# f29h85x_hsm_rtdma_ch_regs register map
Vendor: Texas Instruments
Peripheral module from a debugger description file (folder HSM).
Registers are 32-bit, access per field, no defined reset value unless marked. A register's access mark holds for its fields unless they carry their own. Offsets are as the file gives them; lines under a group give offsets from that group; [hi:lo] are bit positions; {n}, {i} and the like mark numbered series; 'fields as' and 'values as' point back to an identical list; <NAME> marks a mode.

## HSM_RTDMA_CH — HSM RTDMA CH Registers
{0x0+0x1000*i} chan_ctrl[{i}] (i=0..7) group
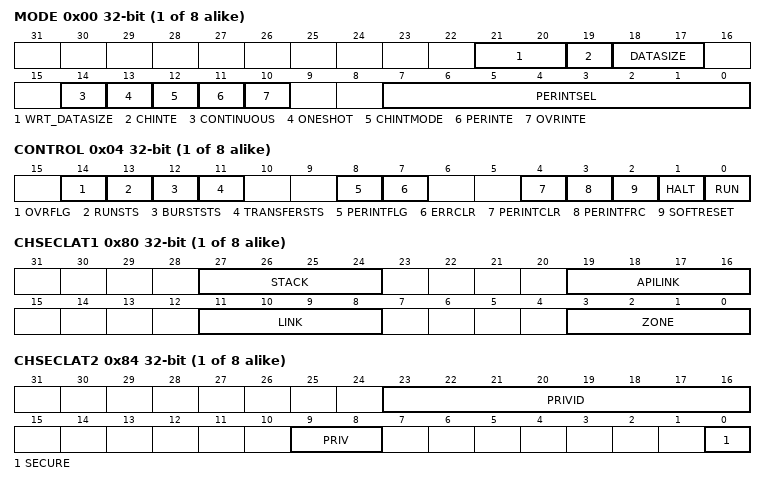
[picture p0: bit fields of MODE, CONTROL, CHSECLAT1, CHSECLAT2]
  0x00 MODE
    [21:20] WRT_DATASIZE rw, [19] CHINTE rw, [18:17] DATASIZE rw, [14] CONTINUOUS rw, [13] ONESHOT rw, [12] CHINTMODE rw, [11] PERINTE rw, [10] OVRINTE rw, [7:0] PERINTSEL rw
  0x04 CONTROL
    [14] OVRFLG ro, [13] RUNSTS ro, [12] BURSTSTS ro, [11] TRANSFERSTS ro, [8] PERINTFLG ro, [7] ERRCLR rw, [4] PERINTCLR rw, [3] PERINTFRC rw, [2] SOFTRESET rw, [1] HALT rw, [0] RUN rw
  0x08 BURST_SIZE
    [7:0] BURSTSIZE rw
  0x0C BURST_COUNT ro
    [7:0] BURSTCOUNT
  0x10 SRC_BURST_STEP
    [15:0] SRCBURSTSTEP rw
  0x14 DST_BURST_STEP
    [15:0] DSTBURSTSTEP rw
  0x18 TRANSFER_SIZE
    [15:0] TRANSFERSIZE rw
  0x1C TRANSFER_COUNT ro
    [15:0] TRANSFERCOUNT
  0x20 SRC_TRANSFER_STEP
    [15:0] SRCTRANSFERSTEP rw
  0x24 DST_TRANSFER_STEP
    [15:0] DSTTRANSFERSTEP rw
  0x28 SRC_WRAP_SIZE
    [15:0] WRAPSIZE rw
  0x2C SRC_WRAP_COUNT ro
    [15:0] WRAPSIZE
  0x30 SRC_WRAP_STEP
    [15:0] WRAPSTEP rw
  0x34 DST_WRAP_SIZE
    [15:0] WRAPSIZE rw
  0x38 DST_WRAP_COUNT ro
    [15:0] WRAPSIZE
  0x3C DST_WRAP_STEP
    [15:0] WRAPSTEP rw
  0x40 SRC_BEG_ADDR_SHADOW rw
    [31:0] BEGADDR
  0x44 SRC_ADDR_SHADOW rw
    [31:0] ADDR
  0x48 SRC_BEG_ADDR_ACTIVE ro
    [31:0] BEGADDR
  0x4C SRC_ADDR_ACTIVE ro
    [31:0] ADDR
  0x50 DST_BEG_ADDR_SHADOW rw
    [31:0] BEGADDR
  0x54 DST_ADDR_SHADOW rw
    [31:0] ADDR
  0x58 DST_BEG_ADDR_ACTIVE ro
    [31:0] BEGADDR
  0x5C DST_ADDR_ACTIVE ro
    [31:0] ADDR
  {0x60+4j} RESERVED_1[{j}] (j=0..7) ro
  0x80 CHSECLAT1 ro
    [27:24] STACK, [19:16] APILINK, [11:8] LINK, [3:0] ZONE
  0x84 CHSECLAT2 ro
    [23:16] PRIVID, [9:8] PRIV, [0] SECURE
  {0x88+4j} RESERVED_2[{j}] (j=0..5) ro
  0xA0 BURST_INTF_CTRL
    [1:0] BURSTCTRL rw
  {0xA4+4j} RESERVED_3[{j}] (j=0..22) ro
  0x100 CHCFG_LOCK
    [0] LOCK rw
  0x104 CHCFG_COMMIT
    [0] COMMIT rw
  {0x108+4j} RESERVED_4[{j}] (j=0..956) ro
